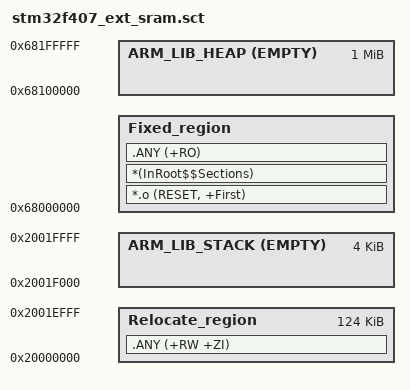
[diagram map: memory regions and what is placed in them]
;*******************************************************************
;* STM32F407 linker scatter file (running code from external SRAM) *
;*******************************************************************

Load_region 0x68000000 0x200000
{
   Fixed_region 0x68000000
   {
      *.o (RESET, +First)
      *(InRoot$$Sections)
      .ANY (+RO)
   }
   
   Relocate_region 0x20000000 0x1F000
   {
      .ANY (+RW +ZI)
   }
   
   ARM_LIB_STACK 0x20020000 EMPTY -0x1000
   {
   }
   
   ARM_LIB_HEAP 0x68100000 EMPTY 0x100000
   {
   }
}
